VERSION "created by canmatrix"

NS_ :

BS_:

BU_: air_ctrl dashboard throttle brakelight_bspd_shutdown bms_core

BO_ 0 Panic: 0 Vector__XXX
 SG_ Panic : 7|2@0+ (1,1) [0|1] "" Vector__XXX

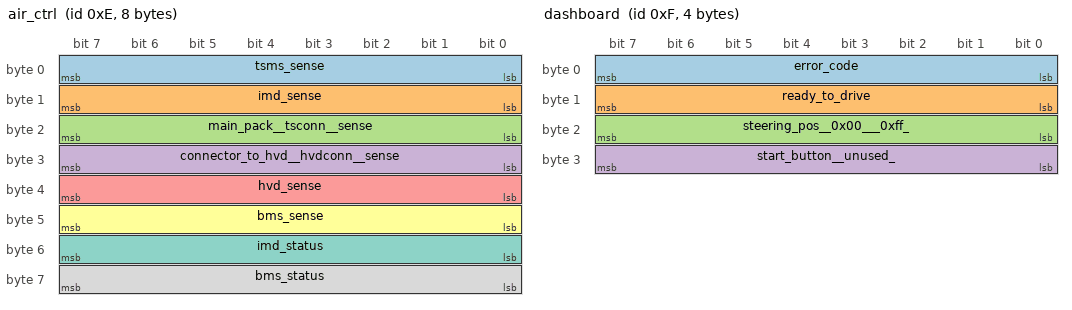
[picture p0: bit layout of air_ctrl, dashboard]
BO_ 14 air_ctrl: 8 air_ctrl
 SG_ tsms_sense : 7|8@0+ (1,0) [0|1] "" bms_core, brakelight_bspd_shutdown, dashboard, throttle
 SG_ imd_sense : 15|8@0+ (1,0) [0|1] "" bms_core, brakelight_bspd_shutdown, dashboard, throttle
 SG_ main_pack__tsconn__sense : 23|8@0+ (1,0) [0|1] "" bms_core, brakelight_bspd_shutdown, dashboard, throttle
 SG_ connector_to_hvd__hvdconn__sense : 31|8@0+ (1,0) [0|1] "" bms_core, brakelight_bspd_shutdown, dashboard, throttle
 SG_ hvd_sense : 39|8@0+ (1,0) [0|1] "" bms_core, brakelight_bspd_shutdown, dashboard, throttle
 SG_ bms_sense : 47|8@0+ (1,0) [0|1] "" bms_core, brakelight_bspd_shutdown, dashboard, throttle
 SG_ imd_status : 55|8@0+ (1,0) [0|1] "" bms_core, brakelight_bspd_shutdown, dashboard, throttle
 SG_ bms_status : 63|8@0+ (1,0) [0|1] "" bms_core, brakelight_bspd_shutdown, dashboard, throttle

BO_ 15 dashboard: 4 dashboard
 SG_ error_code : 7|8@0+ (1,0) [0|1] "" air_ctrl, bms_core, brakelight_bspd_shutdown, throttle
 SG_ ready_to_drive : 15|8@0+ (1,0) [0|1] "" air_ctrl, bms_core, brakelight_bspd_shutdown, throttle
 SG_ steering_pos__0x00___0xff_ : 23|8@0+ (1,0) [0|1] "" air_ctrl, bms_core, brakelight_bspd_shutdown, throttle
 SG_ start_button__unused_ : 31|8@0+ (1,0) [0|1] "" air_ctrl, bms_core, brakelight_bspd_shutdown, throttle

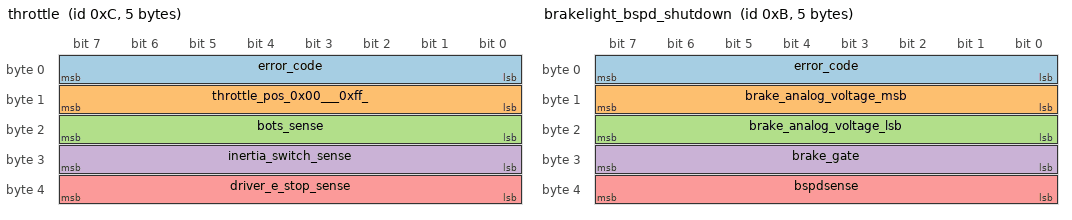
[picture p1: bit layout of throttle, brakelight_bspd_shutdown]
BO_ 12 throttle: 5 throttle
 SG_ error_code : 7|8@0+ (1,0) [0|1] "" air_ctrl, bms_core, brakelight_bspd_shutdown, dashboard
 SG_ throttle_pos_0x00___0xff_ : 15|8@0+ (1,0) [0|1] "" air_ctrl, bms_core, brakelight_bspd_shutdown, dashboard
 SG_ bots_sense : 23|8@0+ (1,0) [0|1] "" air_ctrl, bms_core, brakelight_bspd_shutdown, dashboard
 SG_ inertia_switch_sense : 31|8@0+ (1,0) [0|1] "" air_ctrl, bms_core, brakelight_bspd_shutdown, dashboard
 SG_ driver_e_stop_sense : 39|8@0+ (1,0) [0|1] "" air_ctrl, bms_core, brakelight_bspd_shutdown, dashboard

BO_ 11 brakelight_bspd_shutdown: 5 brakelight_bspd_shutdown
 SG_ error_code : 7|8@0+ (1,0) [0|1] "" air_ctrl, bms_core, dashboard, throttle
 SG_ brake_analog_voltage_msb : 15|8@0+ (1,0) [0|1] "" air_ctrl, bms_core, dashboard, throttle
 SG_ brake_analog_voltage_lsb : 23|8@0+ (1,0) [0|1] "" air_ctrl, bms_core, dashboard, throttle
 SG_ brake_gate : 31|8@0+ (1,0) [0|1] "" air_ctrl, bms_core, dashboard, throttle
 SG_ bspdsense : 39|8@0+ (1,0) [0|1] "" air_ctrl, bms_core, dashboard, throttle

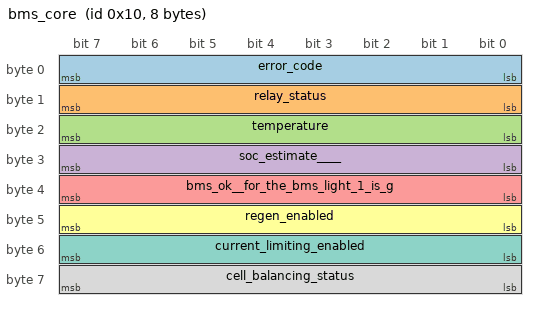
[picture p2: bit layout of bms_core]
BO_ 16 bms_core: 8 bms_core
 SG_ error_code : 7|8@0+ (1,0) [0|1] "" air_ctrl, brakelight_bspd_shutdown, dashboard, throttle
 SG_ relay_status : 15|8@0+ (1,0) [0|1] "" air_ctrl, brakelight_bspd_shutdown, dashboard, throttle
 SG_ temperature : 23|8@0+ (1,0) [0|1] "" air_ctrl, brakelight_bspd_shutdown, dashboard, throttle
 SG_ soc_estimate____ : 31|8@0+ (1,0) [0|1] "" air_ctrl, brakelight_bspd_shutdown, dashboard, throttle
 SG_ bms_ok__for_the_bms_light_1_is_g : 39|8@0+ (1,0) [0|1] "" air_ctrl, brakelight_bspd_shutdown, dashboard, throttle
 SG_ regen_enabled : 47|8@0+ (1,0) [0|1] "" air_ctrl, brakelight_bspd_shutdown, dashboard, throttle
 SG_ current_limiting_enabled : 55|8@0+ (1,0) [0|1] "" air_ctrl, brakelight_bspd_shutdown, dashboard, throttle
 SG_ cell_balancing_status : 63|8@0+ (1,0) [0|1] "" air_ctrl, brakelight_bspd_shutdown, dashboard, throttle

CM_ BO_ 0  "This is bad. Liek really bad";
CM_ BO_ 14  "add comment here";
CM_ BO_ 15  "add comment here";
CM_ BO_ 12  "add comment here";
CM_ BO_ 11  "add comment here";
CM_ BO_ 16  "add comment here";

CM_ BU_ air_ctrl "more comments can go here";
CM_ BU_ dashboard "more comments can go here";
CM_ BU_ throttle "more comments can go here";
CM_ BU_ brakelight_bspd_shutdown "more comments can go here";
CM_ BU_ bms_core "more comments can go here";

BA_DEF_ SG_ "SystemSignalLongSymbol" STRING;

BA_ "SystemSignalLongSymbol" SG_ 16 bms_ok__for_the_bms_light_1_is_g "bms_ok_(for_the_bms_light)1_is_good0_is_bad";
